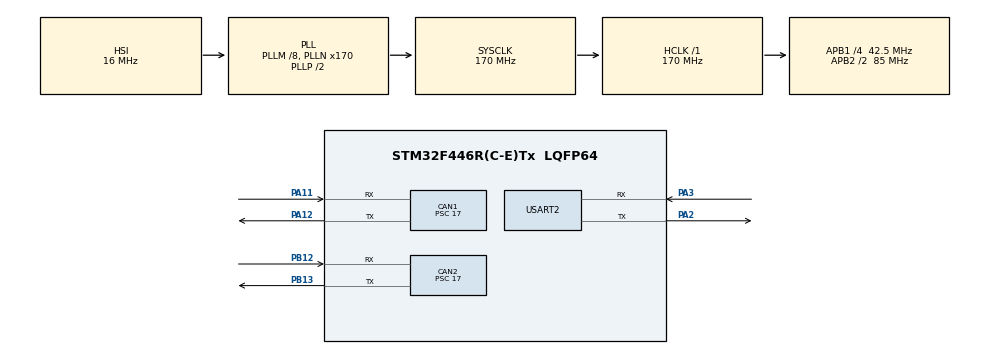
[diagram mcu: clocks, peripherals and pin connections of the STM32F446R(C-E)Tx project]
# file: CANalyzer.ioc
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CAN1.BS2=CAN_BS2_3TQ
CAN1.CalculateBaudRate=500000
CAN1.CalculateTimeBit=2000
CAN1.CalculateTimeQuantum=400.0
CAN1.Prescaler=17
CAN2.BS1=CAN_BS1_2TQ
CAN2.BS2=CAN_BS2_7TQ
CAN2.CalculateBaudRate=250000
CAN2.CalculateTimeBit=4000
CAN2.CalculateTimeQuantum=400.0
CAN2.Prescaler=17
Dma.Request0=USART2_RX
Dma.Request1=USART2_TX
Dma.USART2_RX.0.Direction=DMA_PERIPH_TO_MEMORY
Dma.USART2_RX.0.FIFOMode=DMA_FIFOMODE_DISABLE
Dma.USART2_RX.0.Instance=DMA1_Stream5
Dma.USART2_RX.0.MemDataAlignment=DMA_MDATAALIGN_BYTE
Dma.USART2_RX.0.MemInc=DMA_MINC_ENABLE
Dma.USART2_RX.0.Mode=DMA_NORMAL
Dma.USART2_RX.0.PeriphDataAlignment=DMA_PDATAALIGN_BYTE
Dma.USART2_RX.0.PeriphInc=DMA_PINC_DISABLE
Dma.USART2_RX.0.Priority=DMA_PRIORITY_LOW
Dma.USART2_TX.1.Direction=DMA_MEMORY_TO_PERIPH
Dma.USART2_TX.1.FIFOMode=DMA_FIFOMODE_DISABLE
Dma.USART2_TX.1.Instance=DMA1_Stream6
Dma.USART2_TX.1.MemDataAlignment=DMA_MDATAALIGN_BYTE
Dma.USART2_TX.1.MemInc=DMA_MINC_ENABLE
Dma.USART2_TX.1.Mode=DMA_NORMAL
Dma.USART2_TX.1.PeriphDataAlignment=DMA_PDATAALIGN_BYTE
Dma.USART2_TX.1.PeriphInc=DMA_PINC_DISABLE
Dma.USART2_TX.1.Priority=DMA_PRIORITY_LOW
Mcu.Family=STM32F4
Mcu.Name=STM32F446R(C-E)Tx
Mcu.Package=LQFP64
NVIC.DMA1_Stream5_IRQn=true\:0\:0\:false\:false\:true\:false\:true\:true
NVIC.DMA1_Stream6_IRQn=true\:0\:0\:false\:false\:true\:false\:true\:true
NVIC.PriorityGroup=NVIC_PRIORITYGROUP_4
PA11.Mode=CAN_Activate
PA11.Signal=CAN1_RX
PA12.Mode=CAN_Activate
PA12.Signal=CAN1_TX
PA13.Mode=Serial_Wire
PA13.Signal=SYS_JTMS-SWDIO
PA14.Mode=Serial_Wire
PA14.Signal=SYS_JTCK-SWCLK
PA2.Mode=Asynchronous
PA2.Signal=USART2_TX
PA3.Mode=Asynchronous
PA3.Signal=USART2_RX
PB12.Mode=CAN_Activate
PB12.Signal=CAN2_RX
PB13.Mode=CAN_Activate
PB13.Signal=CAN2_TX
ProjectManager.HeapSize=0x200
ProjectManager.StackSize=0x400
ProjectManager.TargetToolchain=STM32CubeIDE
RCC.AHBFreq_Value=170000000
RCC.APB1CLKDivider=RCC_HCLK_DIV4
RCC.APB1Freq_Value=42500000
RCC.APB1TimFreq_Value=85000000
RCC.APB2CLKDivider=RCC_HCLK_DIV2
RCC.APB2Freq_Value=85000000
RCC.APB2TimFreq_Value=170000000
RCC.CortexFreq_Value=170000000
RCC.HCLKFreq_Value=170000000
RCC.PLLM=8
RCC.PLLN=170
RCC.SYSCLKFreq_VALUE=170000000
RCC.SYSCLKSource=RCC_SYSCLKSOURCE_PLLCLK
RCC.USBFreq_Value=170000000
RCC.VCOOutputFreq_Value=340000000
USART2.VirtualMode=VM_ASYNC
board=custom

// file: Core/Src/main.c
/* USER CODE BEGIN Header */
/**
  ******************************************************************************
  * @file           : main.c
  * @brief          : Main program body
  ******************************************************************************
  * @attention
  *
  * Copyright (c) 2022 STMicroelectronics.
  * All rights reserved.
  *
  * This software is licensed under terms that can be found in the LICENSE file
  * in the root directory of this software component.
  * If no LICENSE file comes with this software, it is provided AS-IS.
  *
  ******************************************************************************
  */
/* USER CODE END Header */
#include "main.h"

/* USER CODE BEGIN Includes */
extern uint8_t buffer[SERIAL_BUFFER_SIZE];
/* USER CODE END Includes */

 CAN_HandleTypeDef hcan1;
CAN_HandleTypeDef hcan2;

UART_HandleTypeDef huart2;
DMA_HandleTypeDef hdma_usart2_rx;
DMA_HandleTypeDef hdma_usart2_tx;

void SystemClock_Config(void);
static void MX_GPIO_Init(void);
static void MX_DMA_Init(void);
static void MX_CAN1_Init(void);
static void MX_CAN2_Init(void);
static void MX_USART2_UART_Init(void);

/* USER CODE BEGIN 0 */

void HAL_UARTEx_RxEventCallback(UART_HandleTypeDef *huart, uint16_t size) {
  if (Serial_IsValidPacket(huart, size)) {
    uint16_t can_id = ((uint16_t)buffer[0] << 8) | buffer[1];
    uint16_t size = buffer[2];
    uint8_t *data = buffer + 3;

    FEB_CAN_transmit(CAN1, can_id, data, size, 1);
  }

  HAL_UARTEx_ReceiveToIdle_DMA(&huart2, buffer, SERIAL_BUFFER_SIZE);
}
/* USER CODE END 0 */

int main(void)
{

  /* MCU Configuration--------------------------------------------------------*/

  /* Reset of all peripherals, Initializes the Flash interface and the Systick. */
  HAL_Init();

  /* Configure the system clock */
  SystemClock_Config();

  /* Initialize all configured peripherals */
  MX_GPIO_Init();
  MX_DMA_Init();
  MX_CAN1_Init();
  MX_CAN2_Init();
  MX_USART2_UART_Init();
  /* USER CODE BEGIN 2 */
  Serial_Init(&huart2, &hdma_usart2_rx, &hdma_usart2_tx);

  Serial_Start();

  /* USER CODE END 2 */

  /* Infinite loop */
  while (1)
  {

  }
}

void SystemClock_Config(void)
{
  RCC_OscInitTypeDef RCC_OscInitStruct = {0};
  RCC_ClkInitTypeDef RCC_ClkInitStruct = {0};

  /** Configure the main internal regulator output voltage
  */
  __HAL_RCC_PWR_CLK_ENABLE();
  __HAL_PWR_VOLTAGESCALING_CONFIG(PWR_REGULATOR_VOLTAGE_SCALE1);

  /** Initializes the RCC Oscillators according to the specified parameters
  * in the RCC_OscInitTypeDef structure.
  */
  RCC_OscInitStruct.OscillatorType = RCC_OSCILLATORTYPE_HSI;
  RCC_OscInitStruct.HSIState = RCC_HSI_ON;
  RCC_OscInitStruct.HSICalibrationValue = RCC_HSICALIBRATION_DEFAULT;
  RCC_OscInitStruct.PLL.PLLState = RCC_PLL_ON;
  RCC_OscInitStruct.PLL.PLLSource = RCC_PLLSOURCE_HSI;
  RCC_OscInitStruct.PLL.PLLM = 8;
  RCC_OscInitStruct.PLL.PLLN = 170;
  RCC_OscInitStruct.PLL.PLLP = RCC_PLLP_DIV2;
  RCC_OscInitStruct.PLL.PLLQ = 2;
  RCC_OscInitStruct.PLL.PLLR = 2;
  if (HAL_RCC_OscConfig(&RCC_OscInitStruct) != HAL_OK)
  {
    Error_Handler();
  }

  /** Activate the Over-Drive mode
  */
  if (HAL_PWREx_EnableOverDrive() != HAL_OK)
  {
    Error_Handler();
  }

  /** Initializes the CPU, AHB and APB buses clocks
  */
  RCC_ClkInitStruct.ClockType = RCC_CLOCKTYPE_HCLK|RCC_CLOCKTYPE_SYSCLK
                              |RCC_CLOCKTYPE_PCLK1|RCC_CLOCKTYPE_PCLK2;
  RCC_ClkInitStruct.SYSCLKSource = RCC_SYSCLKSOURCE_PLLCLK;
  RCC_ClkInitStruct.AHBCLKDivider = RCC_SYSCLK_DIV1;
  RCC_ClkInitStruct.APB1CLKDivider = RCC_HCLK_DIV4;
  RCC_ClkInitStruct.APB2CLKDivider = RCC_HCLK_DIV2;

  if (HAL_RCC_ClockConfig(&RCC_ClkInitStruct, FLASH_LATENCY_5) != HAL_OK)
  {
    Error_Handler();
  }
}

static void MX_CAN1_Init(void)
{

  hcan1.Instance = CAN1;
  hcan1.Init.Prescaler = 17;
  hcan1.Init.Mode = CAN_MODE_NORMAL;
  hcan1.Init.SyncJumpWidth = CAN_SJW_1TQ;
  hcan1.Init.TimeSeg1 = CAN_BS1_1TQ;
  hcan1.Init.TimeSeg2 = CAN_BS2_3TQ;
  hcan1.Init.TimeTriggeredMode = DISABLE;
  hcan1.Init.AutoBusOff = DISABLE;
  hcan1.Init.AutoWakeUp = DISABLE;
  hcan1.Init.AutoRetransmission = DISABLE;
  hcan1.Init.ReceiveFifoLocked = DISABLE;
  hcan1.Init.TransmitFifoPriority = DISABLE;
  if (HAL_CAN_Init(&hcan1) != HAL_OK)
  {
    Error_Handler();
  }

}

static void MX_CAN2_Init(void)
{

  hcan2.Instance = CAN2;
  hcan2.Init.Prescaler = 17;
  hcan2.Init.Mode = CAN_MODE_NORMAL;
  hcan2.Init.SyncJumpWidth = CAN_SJW_1TQ;
  hcan2.Init.TimeSeg1 = CAN_BS1_2TQ;
  hcan2.Init.TimeSeg2 = CAN_BS2_7TQ;
  hcan2.Init.TimeTriggeredMode = DISABLE;
  hcan2.Init.AutoBusOff = DISABLE;
  hcan2.Init.AutoWakeUp = DISABLE;
  hcan2.Init.AutoRetransmission = DISABLE;
  hcan2.Init.ReceiveFifoLocked = DISABLE;
  hcan2.Init.TransmitFifoPriority = DISABLE;
  if (HAL_CAN_Init(&hcan2) != HAL_OK)
  {
    Error_Handler();
  }

}

static void MX_USART2_UART_Init(void)
{

  huart2.Instance = USART2;
  huart2.Init.BaudRate = 115200;
  huart2.Init.WordLength = UART_WORDLENGTH_8B;
  huart2.Init.StopBits = UART_STOPBITS_1;
  huart2.Init.Parity = UART_PARITY_NONE;
  huart2.Init.Mode = UART_MODE_TX_RX;
  huart2.Init.HwFlowCtl = UART_HWCONTROL_NONE;
  huart2.Init.OverSampling = UART_OVERSAMPLING_16;
  if (HAL_UART_Init(&huart2) != HAL_OK)
  {
    Error_Handler();
  }

}

static void MX_DMA_Init(void)
{

  /* DMA controller clock enable */
  __HAL_RCC_DMA1_CLK_ENABLE();

  /* DMA interrupt init */
  /* DMA1_Stream5_IRQn interrupt configuration */
  HAL_NVIC_SetPriority(DMA1_Stream5_IRQn, 0, 0);
  HAL_NVIC_EnableIRQ(DMA1_Stream5_IRQn);
  /* DMA1_Stream6_IRQn interrupt configuration */
  HAL_NVIC_SetPriority(DMA1_Stream6_IRQn, 0, 0);
  HAL_NVIC_EnableIRQ(DMA1_Stream6_IRQn);

}

static void MX_GPIO_Init(void)
{

  /* GPIO Ports Clock Enable */
  __HAL_RCC_GPIOA_CLK_ENABLE();
  __HAL_RCC_GPIOB_CLK_ENABLE();

}

void Error_Handler(void)
{
  __disable_irq();
  while (1)
  {
  }
}
